# AM13E230x register map
Vendor: Texas Instruments; File version: Revised: 2025-12-26 17:30:06
CPU: CM33 r0p0, little endian, MPU, FPU, 4 interrupt priority bits
Registers are 32-bit, read-write, reset 0x0 unless marked. A register's access mark holds for its fields unless they carry their own. Offsets are from the block's base; [hi:lo] are bit positions; lines under a group give offsets from that group; {n}, {i} and the like mark numbered series; 'fields as' and 'values as' point back to an identical list.

## MEMCFG — MEM_CFG_REGS
Base 0x4002A000
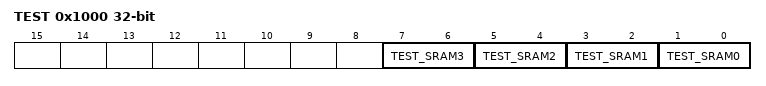
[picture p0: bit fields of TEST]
0x1000 TEST — RAM TEST Register
  [7:6] TEST_SRAM3 — Selects the different test modes for UGLXMP_2 RAM
  [5:4] TEST_SRAM2 — Selects the different test modes for GLXMP_1 RAM
  [3:2] TEST_SRAM1 — Selects the different test modes for GLXMP_0 RAM
  [1:0] TEST_SRAM0 — Selects the different test modes for ULL RAM
0x1010 ROM_WS_CONFIG — ROM wait state configuration
  [0] ROM_WS_ENABLE — ROM wait state 1 enable
0x1014 TMUROM_TEST reset 0x5 — ROM wait state configuration
  [3:0] TMUROM_PAR_FORCE — ROM wait state 1 enable

## PGA0 — PGA_REGS
Base 0x400FC000
Same registers: PGA1 0x400FD000, PGA2 0x400FE000
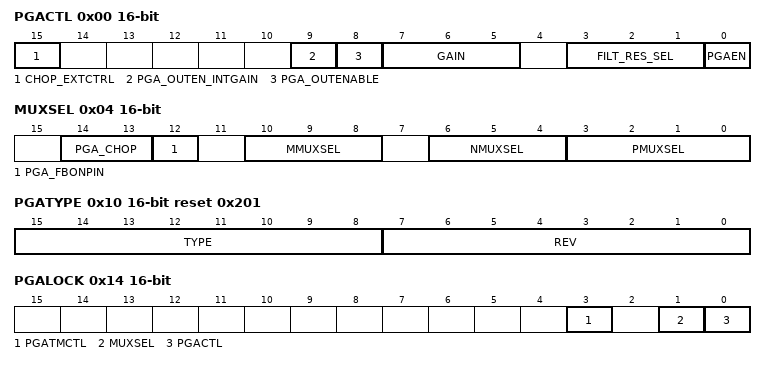
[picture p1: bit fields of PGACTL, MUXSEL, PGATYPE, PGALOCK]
0x00 PGACTL 16-bit — PGA Control Register
  [15] CHOP_EXTCTRL — External Chop Signal Control
  [9] PGA_OUTEN_INTGAIN — PGA Internal Gain Output Enable
  [8] PGA_OUTENABLE — PGA Output Enable
  [7:5] GAIN — PGA gain setting
  [3:1] FILT_RES_SEL — Filter Resistor Select
  [0] PGAEN — PGA Enable
0x04 MUXSEL 16-bit — Mux Selection Register
  [14:13] PGA_CHOP — Chopper Mode Control
  [12] PGA_FBONPIN — Connect PGAOUT to PGA_INM
  [10:8] MMUXSEL — M Mux Select
  [6:4] NMUXSEL — Negative Input Mux Select
  [3:0] PMUXSEL — Positive Input Mux Select
0x10 PGATYPE 16-bit reset 0x201
  [15:8] TYPE ro — PGA Type Field
  [7:0] REV ro — PGA Revision Field
0x14 PGALOCK 16-bit
  [3] PGATMCTL wo — Lock but for PGATMCTL
  [1] MUXSEL wo — Lock bit for MUXSEL
  [0] PGACTL wo — Lock bit for PGACTL.

## SPGSS0 — PERIPHERALREGION
Base 0x4063F000
Same registers: SPGSS1 0x4067F000
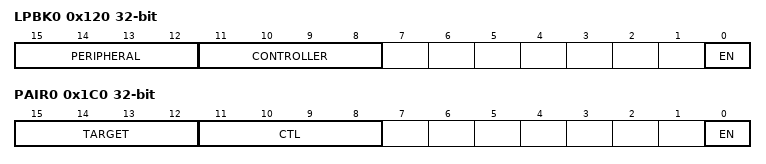
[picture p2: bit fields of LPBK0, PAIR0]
0x120 LPBK0 — Loopback between SPG instances User has to ensure that the SPGs looped back have the same underlying IP instantiated; i.e. both UART, both SPI, both I2C, etc.,
  [15:12] PERIPHERAL — Select SPG peripheral for loopback. Signals invovled in loopback based on interface chosen 1. SPI : CS, SCLK, SDI, SDO 2. I2C : SCL, SDA 3. UART : TX, RX
    {v}=SPG{v+1} (SPG responder select for loopback.) (v=0..15)
  [11:8] CONTROLLER — Select SPG controller for loopback. Signals invovled in loopback based on interface chosen 1. SPI : CS, SCLK, SDI, SDO 2. I2C : SCL, SDA 3. UART : TX, RX
    {v}=SPG{v+1} (SPG commander select for loopback.) (v=0..15)
  [0] EN — Loopback enable
    0=DISABLE (Does not select this clock as a source); 1=ENABLE (Select this clock as a source)
0x1C0 PAIR0 — Pairing of I2C for MULTI-MASTER/SMBUS applications
  [15:12] TARGET — UNICOMM instance for loopback. This instance will be treated as the target
    {v}=SPG{v+1} (SPG responder select for loopback.) (v=0..15)
  [11:8] CTL — UNICOMM instance for loopback. This instance will be treated as the controller.
    {v}=SPG{v+1} (SPG commander select for loopback.) (v=0..15)
  [0] EN — Enable
    values as LPBK0.EN
0xC00 TEST0
  [3:0] DTB_MUX_SEL — This bit field is used to select DTB mux digital output signals.

## UNICOMM0 — PERIPHERALREGION
Base 0x40630000
Same registers: UNICOMM1 0x40632000, UNICOMM2 0x40634000, UNICOMM3 0x40670000, UNICOMM4 0x40672000, UNICOMM5 0x40674000
0x800 GPRCM group
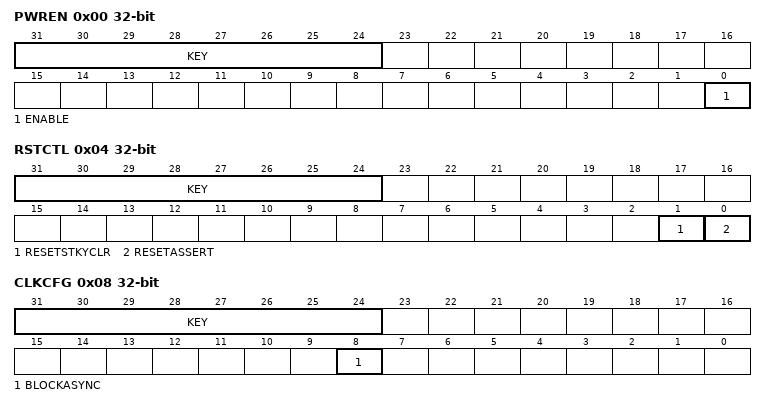
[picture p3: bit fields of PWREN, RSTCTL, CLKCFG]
  0x00 PWREN — Power enable
    [31:24] KEY wo — Write key: the write only takes effect if KEY is 0x26
      38=UNLOCK (KEY to allow write access to this register)
    [0] ENABLE — Power Enable
  0x04 RSTCTL wo — Reset Control
    [31:24] KEY — Write key: the write only takes effect if KEY is 0xB1
      177=UNLOCK (KEY to allow write access to this register)
    [1] RESETSTKYCLR — Reset sticky bit clear
    [0] RESETASSERT — Reset assertion to the peripheral
  0x08 CLKCFG — Peripheral Clock Configuration Register
    [31:24] KEY wo — Write key: the write only takes effect if KEY is 0xA9
      169=UNLOCK (key value to allow change field of GPRCM)
    [8] BLOCKASYNC — Async Clock Request is blocked from starting SYSOSC or forcing bus clock to 32MHz
      0=DISABLE (Not block async clock request); 1=ENABLE (Block async clock request)
  0x14 STAT ro — Status Register
    [16] RESETSTKY — Reset sticky bit
0x1100 IPMODE — Mode Selection Register
  [1:0] SELECT — Free run control
    0=UART (Default functionality is UART); 1=SPI (SPG in SPI Mode); 2=I2C_CONTROLLER (SPG in I2C Controller Mode); 3=I2C_PERIPHERAL (SPG in I2C Peripheral Mode)
